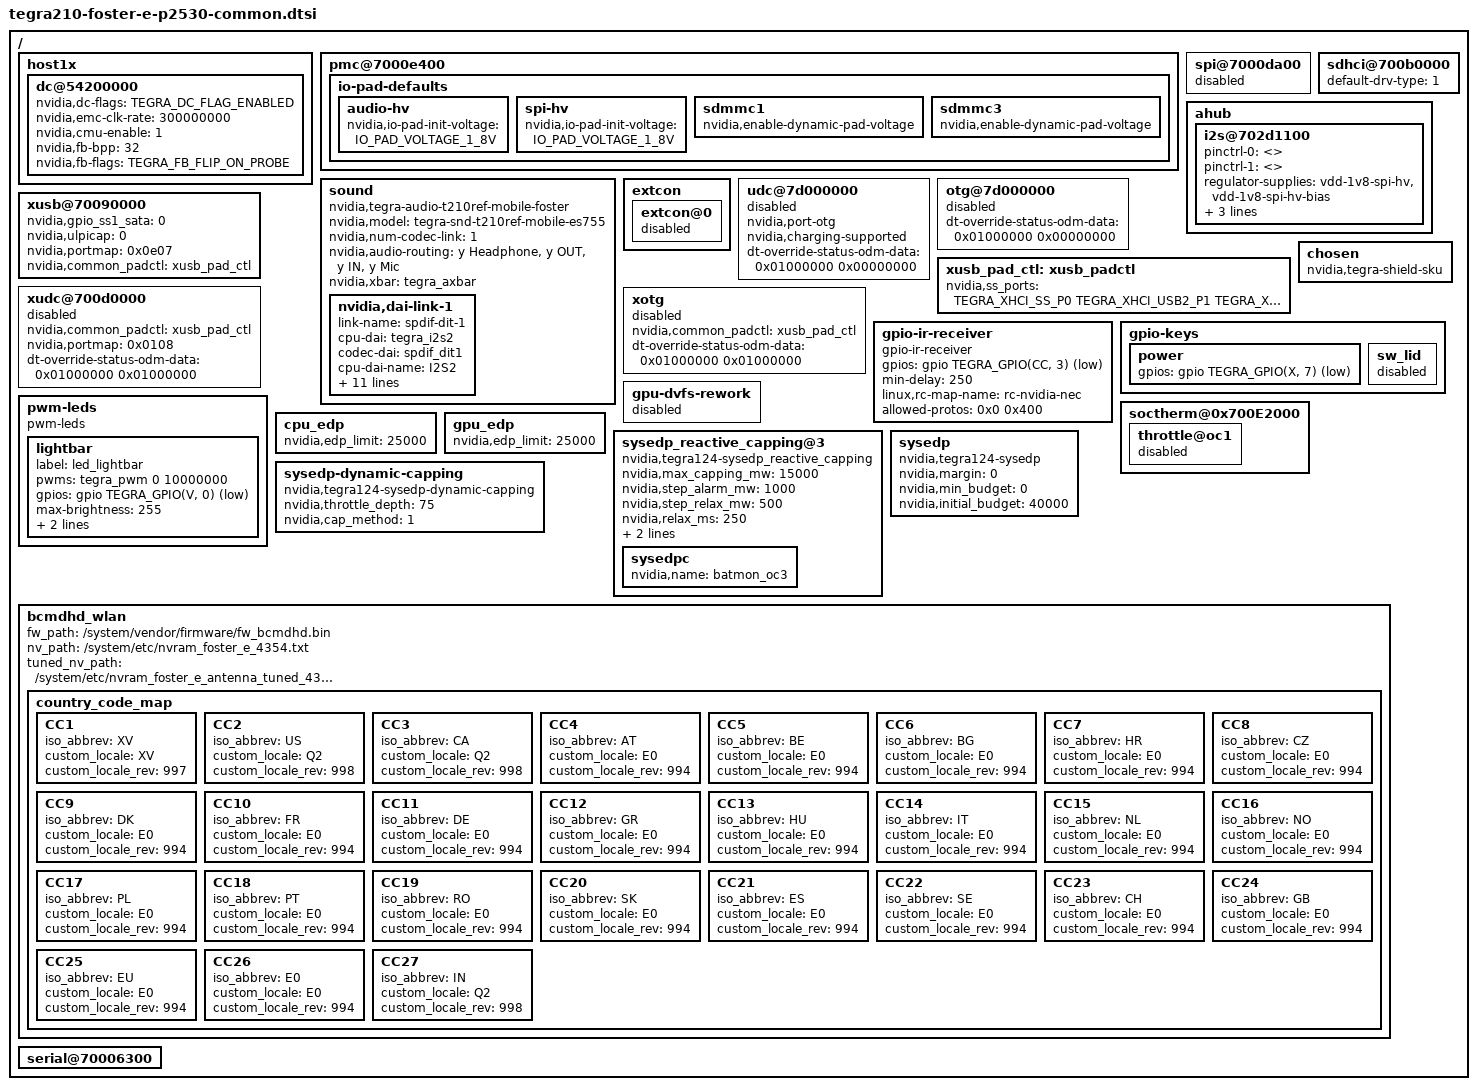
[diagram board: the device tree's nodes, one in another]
/*
 * arch/arm64/boot/dts/tegra210-foster-e-p2530-common.dtsi
 *
 * Copyright (c) 2014-2016, NVIDIA CORPORATION.  All rights reserved.
 *
 * This program is free software; you can redistribute it and/or modify
 * it under the terms of the GNU General Public License as published by
 * the Free Software Foundation; version 2 of the License.
 *
 * This program is distributed in the hope that it will be useful, but WITHOUT
 * ANY WARRANTY; without even the implied warranty of MERCHANTABILITY or
 * FITNESS FOR A PARTICULAR PURPOSE.  See the GNU General Public License for
 * more details.
 *
 * You should have received a copy of the GNU General Public License along
 * with this program; if not, write to the Free Software Foundation, Inc.,
 * 51 Franklin Street, Fifth Floor, Boston, MA  02110-1301, USA.
 *
 */

/dts-v1/;

/memreserve/ 0x80000000 0x00020000;

#include "tegra210-common.dtsi"
#include "tegra210-platforms/tegra210-foster-e-prods.dtsi"
#include "tegra210-platforms/tegra210-sdhci.dtsi"
#include "tegra210-platforms/tegra210-p2530-common.dtsi"
#include "tegra210-platforms/tegra210-foster-e-power-tree-p2530-0932-e00.dtsi"
#include "tegra210-platforms/tegra210-foster-e-gpio-p2530-0930-e00.dtsi"
#include "tegra210-platforms/tegra210-pinmux-drive-sdmmc-common.dtsi"
#include "tegra210-platforms/tegra210-foster-e-pinmux-p2530-0930-e00.dtsi"
#include "tegra210-platforms/tegra210-loki-e-comms.dtsi"
#include "tegra210-platforms/tegra210-foster-e-pwm-fan.dtsi"
#include "tegra210-platforms/tegra210-ers-hdmi-e2190-1100-a00.dtsi"
#include "tegra210-platforms/tegra210-foster-e-thermal-fan-est.dtsi"
#include "tegra210-platforms/tegra210-loki-e-keys-p2530-0032-e00.dtsi"
#include "tegra210-platforms/tegra210-edp.dtsi"
#include <dt-bindings/iio/meter/ina3221x.h>
#include "tegra210-platforms/tegra210-sysedp.dtsi"
#include "tegra210-platforms/tegra210-audio.dtsi"
#include "tegra210-platforms/tegra210-loki-e-cpufreq.dtsi"

/ {
	host1x {
		/* tegradc.0 */
		dc@54200000 {
			status = "okay";
			nvidia,dc-flags = <TEGRA_DC_FLAG_ENABLED>;
			nvidia,emc-clk-rate = <300000000>;
			nvidia,cmu-enable = <1>;
			nvidia,fb-bpp = <32>; /* bits per pixel */
			nvidia,fb-flags = <TEGRA_FB_FLIP_ON_PROBE>;
		};
	};

	pmc@7000e400 {
		io-pad-defaults {
			audio-hv {
				nvidia,io-pad-init-voltage = <IO_PAD_VOLTAGE_1_8V>;
			};

			spi-hv {
				nvidia,io-pad-init-voltage = <IO_PAD_VOLTAGE_1_8V>;
			};

			sdmmc1 {
				nvidia,enable-dynamic-pad-voltage;
			};
			sdmmc3 {
				nvidia,enable-dynamic-pad-voltage;
			};
		};
	};

	spi@7000da00 {
		status = "disabled";
	};

	sdhci@700b0000 {
		default-drv-type = <1>;
	};

	ahub {
		i2s@702d1100 {
			pinctrl-names = "dap_active", "dap_inactive";
			pinctrl-0 = <>;
			pinctrl-1 = <>;
			regulator-supplies = "vdd-1v8-spi-hv", "vdd-1v8-spi-hv-bias";
			vdd-1v8-spi-hv-supply = <&max77620_sd3>;
			vdd-1v8-spi-hv-bias-supply = <&max77620_sd3>;
			fsync-width = <0>;
		};
	};

	sound {
		compatible = "nvidia,tegra-audio-t210ref-mobile-foster";
		nvidia,model = "tegra-snd-t210ref-mobile-es755";
		nvidia,num-codec-link = <1>;

		nvidia,audio-routing =
			"y Headphone", 	"y OUT",
			"y IN",		"y Mic";

		nvidia,xbar = <&tegra_axbar>;

		nvidia,dai-link-1 {
			link-name = "spdif-dit-1";
			cpu-dai = <&tegra_i2s2>;
			codec-dai = <&spdif_dit1>;
			cpu-dai-name = "I2S2";
			codec-dai-name = "dit-hifi";
			format = "dsp_a";
			bitclock-slave;
			frame-slave;
			bitclock-inversion;
			frame-inversion;
			bit-format = "s16_le";
			bclk_ratio = <4>;
			srate = <8000>;
			num-channel = <1>;
			name-prefix = "y";
		};
	};

	extcon {
		extcon@0 {
			status = "disabled";
		};
	};

	udc@7d000000 {
		nvidia,port-otg;
		nvidia,charging-supported;
		#extcon-cells = <1>;
		status = "disabled";
		dt-override-status-odm-data = <0x01000000 0x00000000>;
	};

        otg@7d000000 {
		#extcon-cells = <1>;
		status = "disabled";
		dt-override-status-odm-data = <0x01000000 0x00000000>;
	};

	/* Put common control config here */
	xusb_pad_ctl: xusb_padctl {
		nvidia,ss_ports = < TEGRA_XHCI_SS_P0 TEGRA_XHCI_USB2_P1 TEGRA_XHCI_LANE_6 TEGRA_XHCI_PORT_STD
				    TEGRA_XHCI_SS_P1 TEGRA_XHCI_USB2_P2 TEGRA_XHCI_LANE_5 TEGRA_XHCI_PORT_STD
				    TEGRA_XHCI_SS_P2 TEGRA_XHCI_USB2_P3 TEGRA_XHCI_LANE_0 TEGRA_XHCI_PORT_STD
				    TEGRA_XHCI_SS_P3 TEGRA_XHCI_USB2_P0 TEGRA_XHCI_UNUSED_LANE TEGRA_XHCI_PORT_OTG>;
		status = "okay";
	};

	xusb@70090000 {
		/* nvidia,uses_external_pmic;
		/* nvidia,gpio_controls_muxed_ss_lanes; */
		nvidia,gpio_ss1_sata = <0>;
		nvidia,ulpicap = <0>; /* No ulpi support. can we remove */
		nvidia,portmap = <0x0e07>;
		nvidia,common_padctl = <&xusb_pad_ctl>;
		status = "okay";
	};

	xudc@700d0000 {
		nvidia,common_padctl = <&xusb_pad_ctl>;
		nvidia,portmap = <0x0108>;
		#extcon-cells = <1>;
		status = "disabled";
		dt-override-status-odm-data = <0x01000000 0x01000000>;
	};

	xotg {
		nvidia,common_padctl = <&xusb_pad_ctl>;
		#extcon-cells = <1>;
		status = "disabled";
		dt-override-status-odm-data = <0x01000000 0x01000000>;
	};

	chosen {
		nvidia,tegra-shield-sku;
        };

	gpio-ir-receiver {
		compatible = "gpio-ir-receiver";
		status = "okay";
		gpios = <&gpio TEGRA_GPIO(CC, 3) GPIO_ACTIVE_LOW>;
		min-delay = <250>;
		linux,rc-map-name = "rc-nvidia-nec";
		allowed-protos = <0x0 0x400>;
	};

	gpio-keys {
		power {
			gpios = <&gpio TEGRA_GPIO(X, 7) GPIO_ACTIVE_LOW>;
		};

		sw_lid {
			status="disabled";
		};
	};

	gpu-dvfs-rework {
		status = "disabled";
	};
	pwm-leds {
		compatible = "pwm-leds";
		lightbar {
			label = "led_lightbar";
			pwms = <&tegra_pwm 0 10000000>;
			gpios = <&gpio TEGRA_GPIO(V, 0) GPIO_ACTIVE_LOW>;
			max-brightness = <255>;
			default-brightness = <255>;
			linux,default-trigger = "default-on";
		};
	};

	soctherm@0x700E2000 {
		throttle@oc1 {
			status = "disabled";
		};
	};

	cpu_edp {
		status = "okay";
		nvidia,edp_limit = <25000>;
	};

	gpu_edp {
		status = "okay";
		nvidia,edp_limit = <25000>;
	};

	sysedp_reactive_capping@3 {
		compatible = "nvidia,tegra124-sysedp_reactive_capping";
		nvidia,max_capping_mw = <15000>;
		nvidia,step_alarm_mw = <1000>;
		nvidia,step_relax_mw = <500>;
		nvidia,relax_ms = <250>;
		interrupt-parent = <&soctherm>;
		interrupts = <3 0x2002>;
		sysedpc {
			nvidia,name = "batmon_oc3";
		};
	};

	sysedp {
		compatible = "nvidia,tegra124-sysedp";
		nvidia,margin = <0>;
		nvidia,min_budget = <0>;
		nvidia,initial_budget = <40000>;
	};

	sysedp-dynamic-capping {
		compatible = "nvidia,tegra124-sysedp-dynamic-capping";
		nvidia,throttle_depth = <75>;
		nvidia,cap_method = <1>;
	};

	bcmdhd_wlan {
		fw_path = "/system/vendor/firmware/fw_bcmdhd.bin";
		nv_path = "/system/etc/nvram_foster_e_4354.txt";
		tuned_nv_path = "/system/etc/nvram_foster_e_antenna_tuned_4354.txt";
		country_code_map {
			CC1 {
				iso_abbrev = "XV";
				custom_locale = "XV";
				custom_locale_rev = <997>;
			};
			CC2 {
				iso_abbrev = "US";
				custom_locale = "Q2";
				custom_locale_rev = <998>;
			};
			CC3 {
				iso_abbrev = "CA";
				custom_locale = "Q2";
				custom_locale_rev = <998>;
			};
			CC4 {
				iso_abbrev = "AT";
				custom_locale = "E0";
				custom_locale_rev = <994>;
			};
			CC5 {
				iso_abbrev = "BE";
				custom_locale = "E0";
				custom_locale_rev = <994>;
			};
			CC6 {
				iso_abbrev = "BG";
				custom_locale = "E0";
				custom_locale_rev = <994>;
			};
			CC7 {
				iso_abbrev = "HR";
				custom_locale = "E0";
				custom_locale_rev = <994>;
			};
			CC8 {
				iso_abbrev = "CZ";
				custom_locale = "E0";
				custom_locale_rev = <994>;
			};
			CC9 {
				iso_abbrev = "DK";
				custom_locale = "E0";
				custom_locale_rev = <994>;
			};
			CC10 {
				iso_abbrev = "FR";
				custom_locale = "E0";
				custom_locale_rev = <994>;
			};
			CC11 {
				iso_abbrev = "DE";
				custom_locale = "E0";
				custom_locale_rev = <994>;
			};
			CC12 {
				iso_abbrev = "GR";
				custom_locale = "E0";
				custom_locale_rev = <994>;
			};
			CC13 {
				iso_abbrev = "HU";
				custom_locale = "E0";
				custom_locale_rev = <994>;
			};
			CC14 {
				iso_abbrev = "IT";
				custom_locale = "E0";
				custom_locale_rev = <994>;
			};
			CC15 {
				iso_abbrev = "NL";
				custom_locale = "E0";
				custom_locale_rev = <994>;
			};
			CC16 {
				iso_abbrev = "NO";
				custom_locale = "E0";
				custom_locale_rev = <994>;
			};
			CC17 {
				iso_abbrev = "PL";
				custom_locale = "E0";
				custom_locale_rev = <994>;
			};
			CC18 {
				iso_abbrev = "PT";
				custom_locale = "E0";
				custom_locale_rev = <994>;
			};
			CC19 {
				iso_abbrev = "RO";
				custom_locale = "E0";
				custom_locale_rev = <994>;
			};
			CC20 {
				iso_abbrev = "SK";
				custom_locale = "E0";
				custom_locale_rev = <994>;
			};
			CC21 {
				iso_abbrev = "ES";
				custom_locale = "E0";
				custom_locale_rev = <994>;
			};
			CC22 {
				iso_abbrev = "SE";
				custom_locale = "E0";
				custom_locale_rev = <994>;
			};
			CC23 {
				iso_abbrev = "CH";
				custom_locale = "E0";
				custom_locale_rev = <994>;
			};
			CC24 {
				iso_abbrev = "GB";
				custom_locale = "E0";
				custom_locale_rev = <994>;
			};
			CC25 {
				iso_abbrev = "EU";
				custom_locale = "E0";
				custom_locale_rev = <994>;
			};
			CC26 {
				iso_abbrev = "E0";
				custom_locale = "E0";
				custom_locale_rev = <994>;
			};
			CC27 {
				iso_abbrev = "IN";
				custom_locale = "Q2";
				custom_locale_rev = <998>;
			};
		};
	};

	serial@70006300 {
		dma-names = "tx";
	};
};
